VERSION ""

NS_ :

BS_:

BU_: SIMP VCU

VAL_TABLE_ DriveMode 4 "SPOT_TURN" 3 "RIGHT" 2 "LEFT" 1 "REVERSE" 0 "FORWARD" ;
VAL_TABLE_ DriveModeStatus 1 "READY" 0 "ALIGNING" ;

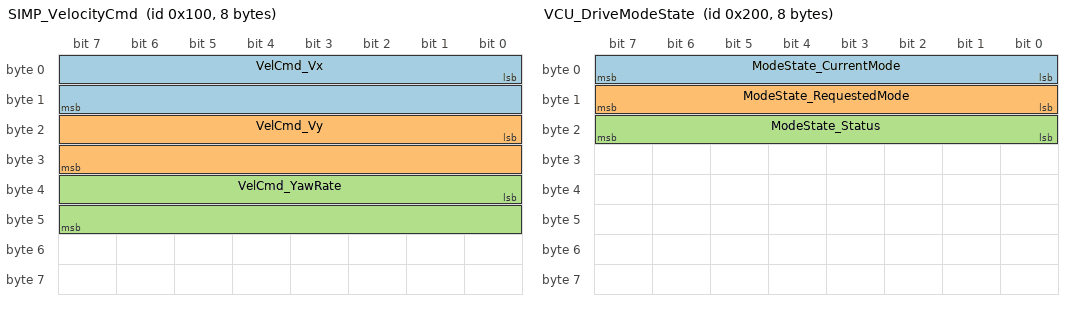
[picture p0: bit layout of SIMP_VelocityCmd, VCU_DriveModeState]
BO_ 256 SIMP_VelocityCmd: 8 SIMP
 SG_ VelCmd_Vx : 0|16@1- (0.001,0) [-32.768|32.767] "m/s" VCU
 SG_ VelCmd_Vy : 16|16@1- (0.001,0) [-32.768|32.767] "m/s" VCU
 SG_ VelCmd_YawRate : 32|16@1- (0.0001,0) [-3.2768|3.2767] "rad/s" VCU

BO_ 257 SIMP_DriveModeCmd: 8 SIMP
 SG_ ModeCmd_RequestedMode : 0|8@1+ (1,0) [0|4] "" VCU

BO_ 512 VCU_DriveModeState: 8 VCU
 SG_ ModeState_CurrentMode : 0|8@1+ (1,0) [0|4] "" SIMP
 SG_ ModeState_RequestedMode : 8|8@1+ (1,0) [0|4] "" SIMP
 SG_ ModeState_Status : 16|8@1+ (1,0) [0|1] "" SIMP

CM_ BU_ SIMP "SIMP planner + simp_tracker ECU (ROS 2).";
CM_ BU_ VCU "Vehicle control unit of the e-Corner vehicle.";
CM_ BO_ 256 "ROS /cmd_vel (geometry_msgs/Twist) from simp_tracker, 100 Hz. Zero command when no valid trajectory point.";
CM_ SG_ 256 VelCmd_Vx "Twist.linear.x, body-frame longitudinal velocity.";
CM_ SG_ 256 VelCmd_Vy "Twist.linear.y, body-frame lateral velocity.";
CM_ SG_ 256 VelCmd_YawRate "Twist.angular.z, body yaw rate.";
CM_ BO_ 257 "ROS /vehicle/drive_mode_command (std_msgs/UInt8) from simp_tracker. Sent only when a valid trajectory point exists.";
CM_ SG_ 257 ModeCmd_RequestedMode "TrackingTrajectoryPoint.requested_mode (DriveModeState constants).";
CM_ BO_ 512 "ROS /vehicle/drive_mode_state (simp_planner_msgs/DriveModeState), 20 Hz.";
CM_ SG_ 512 ModeState_CurrentMode "DriveModeState.current_mode.";
CM_ SG_ 512 ModeState_RequestedMode "DriveModeState.requested_mode.";
CM_ SG_ 512 ModeState_Status "DriveModeState.status.";

BA_DEF_  "BusType" STRING ;
BA_DEF_ BO_  "GenMsgCycleTime" INT 0 65535;
BA_DEF_ BO_  "GenMsgSendType" ENUM  "Cyclic","Event","IfActive";
BA_DEF_DEF_  "BusType" "CAN";
BA_DEF_DEF_  "GenMsgCycleTime" 0;
BA_DEF_DEF_  "GenMsgSendType" "Cyclic";
BA_ "GenMsgCycleTime" BO_ 256 10;
BA_ "GenMsgCycleTime" BO_ 257 10;
BA_ "GenMsgSendType" BO_ 257 2;
BA_ "GenMsgCycleTime" BO_ 512 50;

VAL_ 257 ModeCmd_RequestedMode 4 "SPOT_TURN" 3 "RIGHT" 2 "LEFT" 1 "REVERSE" 0 "FORWARD" ;
VAL_ 512 ModeState_CurrentMode 4 "SPOT_TURN" 3 "RIGHT" 2 "LEFT" 1 "REVERSE" 0 "FORWARD" ;
VAL_ 512 ModeState_RequestedMode 4 "SPOT_TURN" 3 "RIGHT" 2 "LEFT" 1 "REVERSE" 0 "FORWARD" ;
VAL_ 512 ModeState_Status 1 "READY" 0 "ALIGNING" ;
